# S6E1B3xG register map
Vendor: Cypress; File version: 2.1
CPU: CM0PLUS r0p1, little endian, no MPU, no FPU, 2 interrupt priority bits
Registers are 8-bit, read-write, reset 0x0 unless marked. A register's access mark holds for its fields unless they carry their own. Offsets are from the block's base; [hi:lo] are bit positions; {n}, {i} and the like mark numbered series.

## GPIO — I/O Port Registers
Base 0x40033000
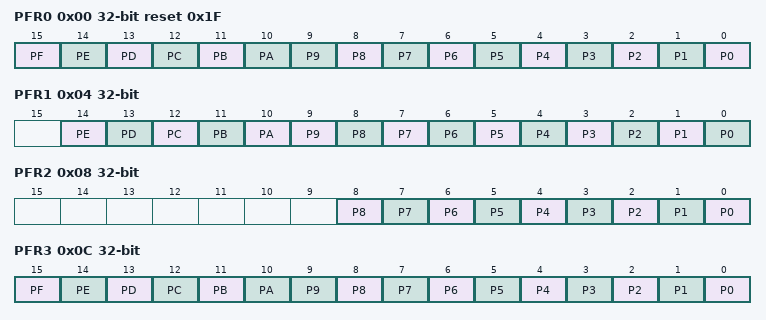
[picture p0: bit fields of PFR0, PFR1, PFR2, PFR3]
0x00 PFR0 32-bit reset 0x1F — Port Function Setting Register 0 [BHW]
  [15] PF — Bit15 of PFR0
  [14] PE — Bit14 of PFR0
  [13] PD — Bit13 of PFR0
  [12] PC — Bit12 of PFR0
  [11] PB — Bit11 of PFR0
  [10] PA — Bit10 of PFR0
  [n] P{n} (n=0..9) — Bit{n} of PFR0
0x04 PFR1 32-bit — Port Function Setting Register 1 [BHW]
  [14] PE — Bit14 of PFR1
  [13] PD — Bit13 of PFR1
  [12] PC — Bit12 of PFR1
  [11] PB — Bit11 of PFR1
  [10] PA — Bit10 of PFR1
  [n] P{n} (n=0..9) — Bit{n} of PFR1
0x08 PFR2 32-bit — Port Function Setting Register 2 [BHW]
  [n] P{n} (n=0..8) — Bit{n} of PFR2
0x0C PFR3 32-bit — Port Function Setting Register 3 [BHW]
  [15] PF — Bit15 of PFR3
  [14] PE — Bit14 of PFR3
  [13] PD — Bit13 of PFR3
  [12] PC — Bit12 of PFR3
  [11] PB — Bit11 of PFR3
  [10] PA — Bit10 of PFR3
  [n] P{n} (n=0..9) — Bit{n} of PFR3
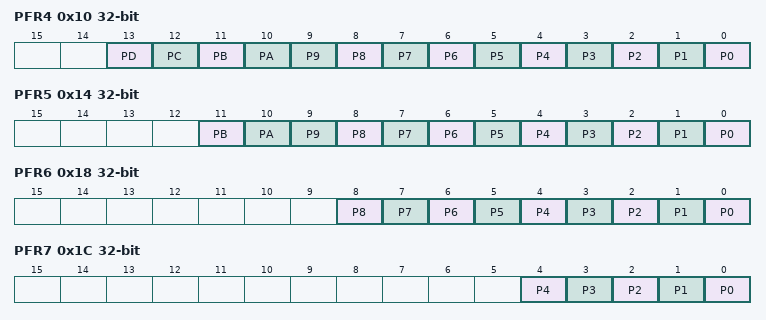
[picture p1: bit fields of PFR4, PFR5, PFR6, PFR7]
0x10 PFR4 32-bit — Port Function Setting Register 4 [HW]
  [13] PD — Bit13 of PFR4
  [12] PC — Bit12 of PFR4
  [11] PB — Bit11 of PFR4
  [10] PA — Bit10 of PFR4
  [n] P{n} (n=0..9) — Bit{n} of PFR4
0x14 PFR5 32-bit — Port Function Setting Register 5 [BHW]
  [11] PB — Bit11 of PFR5
  [10] PA — Bit10 of PFR5
  [n] P{n} (n=0..9) — Bit{n} of PFR5
0x18 PFR6 32-bit — Port Function Setting Register 6 [BHW]
  [n] P{n} (n=0..8) — Bit{n} of PFR6
0x1C PFR7 32-bit — Port Function Setting Register 7 [BHW]
  [n] P{n} (n=0..4) — Bit{n} of PFR7
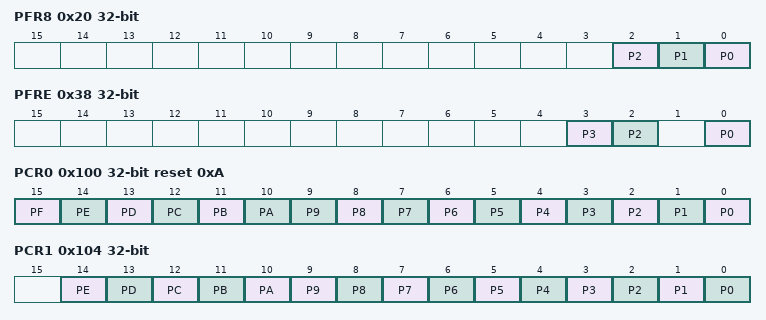
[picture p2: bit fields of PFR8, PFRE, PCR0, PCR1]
0x20 PFR8 32-bit — Port Function Setting Register 8 [BHW]
  [2] P2 — Bit2 of PFR8
  [1] P1 — Bit1 of PFR8
  [0] P0 — Bit0 of PFR8
0x24 PFR9 32-bit reset not defined — Port Function Setting Register 9 [BHW]
0x28 PFRA 32-bit reset not defined — Port Function Setting Register A [BHW]
0x2C PFRB 32-bit reset not defined — Port Function Setting Register B [BHW]
0x30 PFRC 32-bit reset not defined — Port Function Setting Register C [BHW]
0x34 PFRD 32-bit reset not defined — Port Function Setting Register D [BHW]
0x38 PFRE 32-bit — Port Function Setting Register E [BHW]
  [3] P3 — Bit3 of PFRE
  [2] P2 — Bit2 of PFRE
  [0] P0 — Bit0 of PFRE
0x3C PFRF 32-bit reset not defined — Port Function Setting Register F [BHW]
0x100 PCR0 32-bit reset 0xA — Pull-up Setting Register 0 [BHW]
  [15] PF — Bit15 of PCR0
  [14] PE — Bit14 of PCR0
  [13] PD — Bit13 of PCR0
  [12] PC — Bit12 of PCR0
  [11] PB — Bit11 of PCR0
  [10] PA — Bit10 of PCR0
  [n] P{n} (n=0..9) — Bit{n} of PCR0
0x104 PCR1 32-bit — Pull-up Setting Register 1 [BHW]
  [14] PE — Bit14 of PCR1
  [13] PD — Bit13 of PCR1
  [12] PC — Bit12 of PCR1
  [11] PB — Bit11 of PCR1
  [10] PA — Bit10 of PCR1
  [n] P{n} (n=0..9) — Bit{n} of PCR1
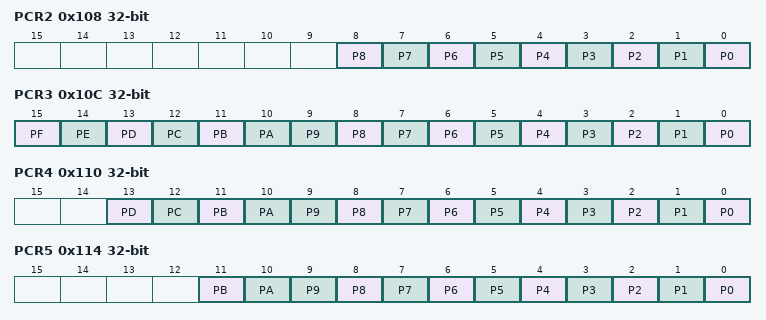
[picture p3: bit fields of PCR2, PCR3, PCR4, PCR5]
0x108 PCR2 32-bit — Pull-up Setting Register 2 [BHW]
  [n] P{n} (n=0..8) — Bit{n} of PCR2
0x10C PCR3 32-bit — Pull-up Setting Register 3 [BHW]
  [15] PF — Bit15 of PCR3
  [14] PE — Bit14 of PCR3
  [13] PD — Bit13 of PCR3
  [12] PC — Bit12 of PCR3
  [11] PB — Bit11 of PCR3
  [10] PA — Bit10 of PCR3
  [n] P{n} (n=0..9) — Bit{n} of PCR3
0x110 PCR4 32-bit — Pull-up Setting Register 4 [BHW]
  [13] PD — Bit13 of PCR4
  [12] PC — Bit12 of PCR4
  [11] PB — Bit11 of PCR4
  [10] PA — Bit10 of PCR4
  [n] P{n} (n=0..9) — Bit{n} of PCR4
0x114 PCR5 32-bit — Pull-up Setting Register 5 [BHW]
  [11] PB — Bit11 of PCR5
  [10] PA — Bit10 of PCR5
  [n] P{n} (n=0..9) — Bit{n} of PCR5
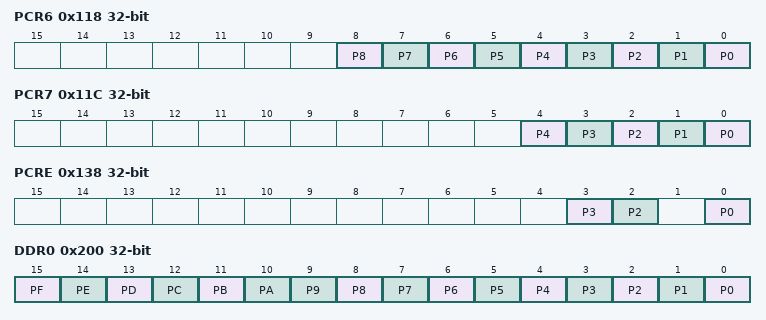
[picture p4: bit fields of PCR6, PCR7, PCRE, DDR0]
0x118 PCR6 32-bit — Pull-up Setting Register 6 [BHW]
  [n] P{n} (n=0..8) — Bit{n} of PCR6
0x11C PCR7 32-bit — Pull-up Setting Register 7 [BHW]
  [n] P{n} (n=0..4) — Bit{n} of PCR7
0x124 PCR9 32-bit reset not defined — Pull-up Setting Register 9 [BHW]
0x128 PCRA 32-bit reset not defined — Pull-up Setting Register A [BHW]
0x12C PCRB 32-bit reset not defined — Pull-up Setting Register B [BHW]
0x130 PCRC 32-bit reset not defined — Pull-up Setting Register C [BHW]
0x134 PCRD 32-bit reset not defined — Pull-up Setting Register D [BHW]
0x138 PCRE 32-bit — Pull-up Setting Register E [BHW]
  [3] P3 — Bit3 of PCRE
  [2] P2 — Bit2 of PCRE
  [0] P0 — Bit0 of PCRE
0x13C PCRF 32-bit reset not defined — Pull-up Setting Register F [BHW]
0x200 DDR0 32-bit — Port input/output Direction Setting Register 0 [BHW]
  [15] PF — Bit15 of DDR0
  [14] PE — Bit14 of DDR0
  [13] PD — Bit13 of DDR0
  [12] PC — Bit12 of DDR0
  [11] PB — Bit11 of DDR0
  [10] PA — Bit10 of DDR0
  [n] P{n} (n=0..9) — Bit{n} of DDR0
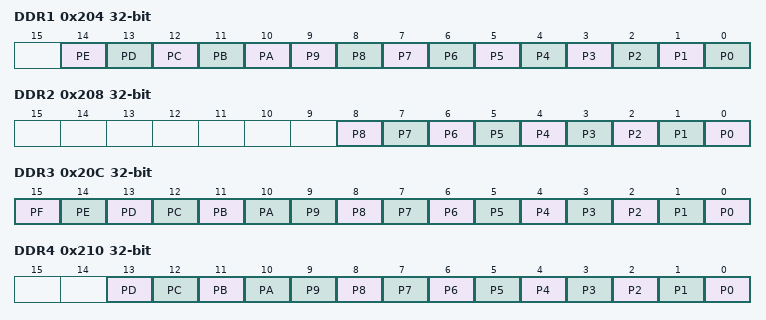
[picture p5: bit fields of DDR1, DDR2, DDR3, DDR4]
0x204 DDR1 32-bit — Port input/output Direction Setting Register 1 [BHW]
  [14] PE — Bit14 of DDR1
  [13] PD — Bit13 of DDR1
  [12] PC — Bit12 of DDR1
  [11] PB — Bit11 of DDR1
  [10] PA — Bit10 of DDR1
  [n] P{n} (n=0..9) — Bit{n} of DDR1
0x208 DDR2 32-bit — Port input/output Direction Setting Register 2 [BHW]
  [n] P{n} (n=0..8) — Bit{n} of DDR2
0x20C DDR3 32-bit — Port input/output Direction Setting Register 3 [BHW]
  [15] PF — Bit15 of DDR3
  [14] PE — Bit14 of DDR3
  [13] PD — Bit13 of DDR3
  [12] PC — Bit12 of DDR3
  [11] PB — Bit11 of DDR3
  [10] PA — Bit10 of DDR3
  [n] P{n} (n=0..9) — Bit{n} of DDR3
0x210 DDR4 32-bit — Port input/output Direction Setting Register 4 [BHW]
  [13] PD — Bit13 of DDR4
  [12] PC — Bit12 of DDR4
  [11] PB — Bit11 of DDR4
  [10] PA — Bit10 of DDR4
  [n] P{n} (n=0..9) — Bit{n} of DDR4
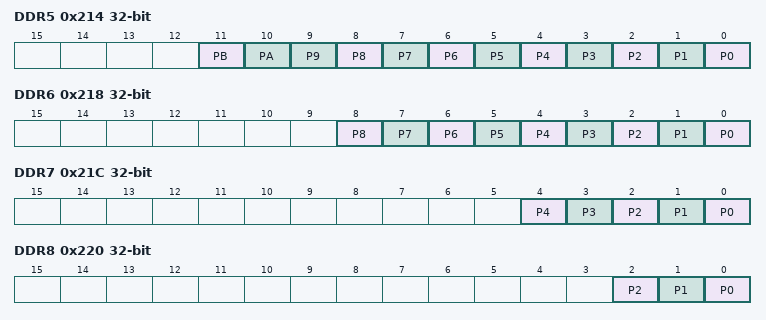
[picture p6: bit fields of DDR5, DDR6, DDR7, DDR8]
0x214 DDR5 32-bit — Port input/output Direction Setting Register 5 [BHW]
  [11] PB — Bit11 of DDR5
  [10] PA — Bit10 of DDR5
  [n] P{n} (n=0..9) — Bit{n} of DDR5
0x218 DDR6 32-bit — Port input/output Direction Setting Register 6 [BHW]
  [n] P{n} (n=0..8) — Bit{n} of DDR6
0x21C DDR7 32-bit — Port input/output Direction Setting Register 7 [BHW]
  [n] P{n} (n=0..4) — Bit{n} of DDR7
0x220 DDR8 32-bit — Port input/output Direction Setting Register 8 [BHW]
  [2] P2 — Bit2 of DDR8
  [1] P1 — Bit1 of DDR8
  [0] P0 — Bit0 of DDR8
0x224 DDR9 32-bit reset not defined — Port input/output Direction Setting Register 9 [BHW]
0x228 DDRA 32-bit reset not defined — Port input/output Direction Setting Register A [BHW]
0x22C DDRB 32-bit reset not defined — Port input/output Direction Setting Register B [BHW]
0x230 DDRC 32-bit reset not defined — Port input/output Direction Setting Register C [BHW]
0x234 DDRD 32-bit reset not defined — Port input/output Direction Setting Register D [BHW]
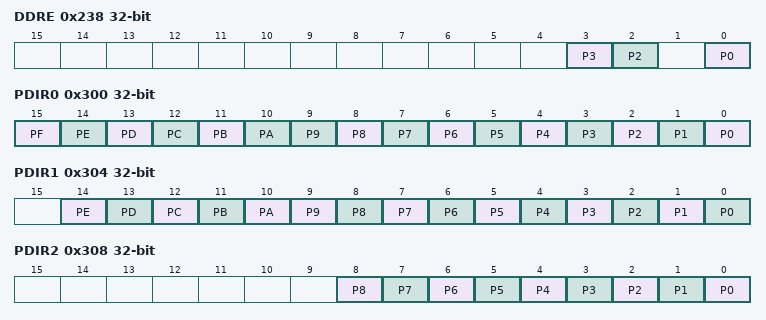
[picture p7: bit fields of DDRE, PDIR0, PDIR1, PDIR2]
0x238 DDRE 32-bit — Port input/output Direction Setting Register E [BHW]
  [3] P3 — Bit3 of DDRE
  [2] P2 — Bit2 of DDRE
  [0] P0 — Bit0 of DDRE
0x23C DDRF 32-bit reset not defined — Port input/output Direction Setting Register F [BHW]
0x300 PDIR0 32-bit ro — Port Input Data Register 0 [BHW]
  [15] PF rw — Bit15 of PDIR0
  [14] PE rw — Bit14 of PDIR0
  [13] PD rw — Bit13 of PDIR0
  [12] PC rw — Bit12 of PDIR0
  [11] PB rw — Bit11 of PDIR0
  [10] PA rw — Bit10 of PDIR0
  [n] P{n} rw (n=0..9) — Bit{n} of PDIR0
0x304 PDIR1 32-bit ro — Port Input Data Register 1 [BHW]
  [14] PE rw — Bit14 of PDIR1
  [13] PD rw — Bit13 of PDIR1
  [12] PC rw — Bit12 of PDIR1
  [11] PB rw — Bit11 of PDIR1
  [10] PA rw — Bit10 of PDIR1
  [n] P{n} rw (n=0..9) — Bit{n} of PDIR1
0x308 PDIR2 32-bit ro — Port Input Data Register 2 [BHW]
  [n] P{n} rw (n=0..8) — Bit{n} of PDIR2
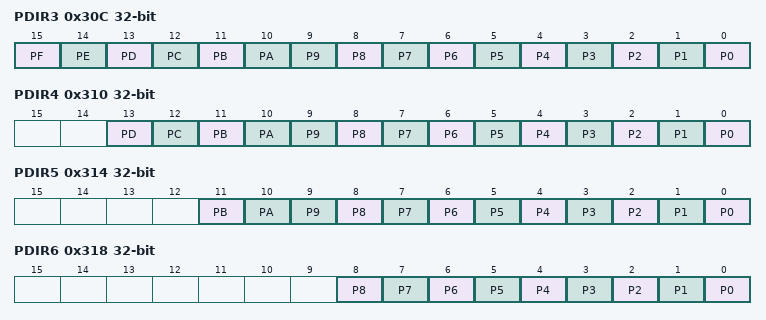
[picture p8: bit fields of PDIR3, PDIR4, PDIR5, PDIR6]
0x30C PDIR3 32-bit ro — Port Input Data Register 3 [BHW]
  [15] PF rw — Bit15 of PDIR3
  [14] PE rw — Bit14 of PDIR3
  [13] PD rw — Bit13 of PDIR3
  [12] PC rw — Bit12 of PDIR3
  [11] PB rw — Bit11 of PDIR3
  [10] PA rw — Bit10 of PDIR3
  [n] P{n} rw (n=0..9) — Bit{n} of PDIR3
0x310 PDIR4 32-bit ro — Port Input Data Register 4 [BHW]
  [13] PD rw — Bit13 of PDIR4
  [12] PC rw — Bit12 of PDIR4
  [11] PB rw — Bit11 of PDIR4
  [10] PA rw — Bit10 of PDIR4
  [n] P{n} rw (n=0..9) — Bit{n} of PDIR4
0x314 PDIR5 32-bit ro — Port Input Data Register 5 [BHW]
  [11] PB rw — Bit11 of PDIR5
  [10] PA rw — Bit10 of PDIR5
  [n] P{n} rw (n=0..9) — Bit{n} of PDIR5
0x318 PDIR6 32-bit ro — Port Input Data Register 6 [BHW]
  [n] P{n} rw (n=0..8) — Bit{n} of PDIR6
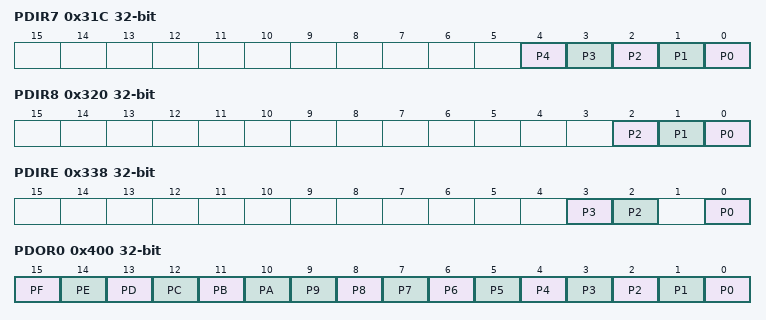
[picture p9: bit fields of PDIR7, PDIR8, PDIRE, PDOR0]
0x31C PDIR7 32-bit ro — Port Input Data Register 7 [BHW]
  [n] P{n} rw (n=0..4) — Bit{n} of PDIR7
0x320 PDIR8 32-bit ro — Port Input Data Register 8 [BHW]
  [2] P2 rw — Bit2 of PDIR8
  [1] P1 rw — Bit1 of PDIR8
  [0] P0 rw — Bit0 of PDIR8
0x324 PDIR9 32-bit ro reset not defined — Port Input Data Register 9 [BHW]
0x328 PDIRA 32-bit ro reset not defined — Port Input Data Register A [BHW]
0x32C PDIRB 32-bit ro reset not defined — Port Input Data Register B [BHW]
0x330 PDIRC 32-bit ro reset not defined — Port Input Data Register C [BHW]
0x334 PDIRD 32-bit ro reset not defined — Port Input Data Register D [BHW]
0x338 PDIRE 32-bit ro — Port Input Data Register E [BHW]
  [3] P3 rw — Bit3 of PDIRE
  [2] P2 rw — Bit2 of PDIRE
  [0] P0 rw — Bit0 of PDIRE
0x33C PDIRF 32-bit ro reset not defined — Port Input Data Register F [BHW]
0x400 PDOR0 32-bit — Port Output Data Register 0 [BHW]
  [15] PF — Bit15 of PDOR0
  [14] PE — Bit14 of PDOR0
  [13] PD — Bit13 of PDOR0
  [12] PC — Bit12 of PDOR0
  [11] PB — Bit11 of PDOR0
  [10] PA — Bit10 of PDOR0
  [n] P{n} (n=0..9) — Bit{n} of PDOR0
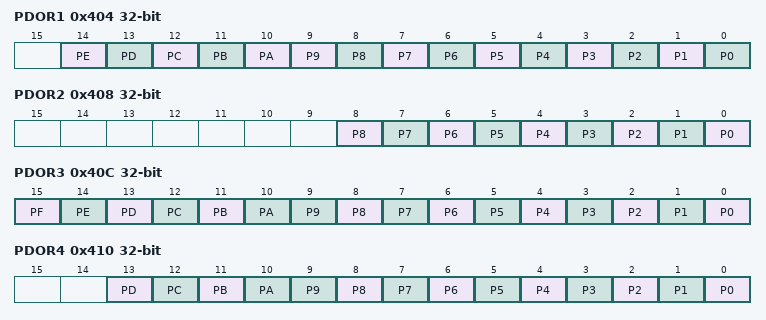
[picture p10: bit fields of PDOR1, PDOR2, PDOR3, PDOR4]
0x404 PDOR1 32-bit — Port Output Data Register 1 [BHW]
  [14] PE — Bit14 of PDOR1
  [13] PD — Bit13 of PDOR1
  [12] PC — Bit12 of PDOR1
  [11] PB — Bit11 of PDOR1
  [10] PA — Bit10 of PDOR1
  [n] P{n} (n=0..9) — Bit{n} of PDOR1
0x408 PDOR2 32-bit — Port Output Data Register 2 [BHW]
  [n] P{n} (n=0..8) — Bit{n} of PDOR2
0x40C PDOR3 32-bit — Port Output Data Register 3 [BHW]
  [15] PF — Bit15 of PDOR3
  [14] PE — Bit14 of PDOR3
  [13] PD — Bit13 of PDOR3
  [12] PC — Bit12 of PDOR3
  [11] PB — Bit11 of PDOR3
  [10] PA — Bit10 of PDOR3
  [n] P{n} (n=0..9) — Bit{n} of PDOR3
0x410 PDOR4 32-bit — Port Output Data Register 4 [BHW]
  [13] PD — Bit13 of PDOR4
  [12] PC — Bit12 of PDOR4
  [11] PB — Bit11 of PDOR4
  [10] PA — Bit10 of PDOR4
  [n] P{n} (n=0..9) — Bit{n} of PDOR4
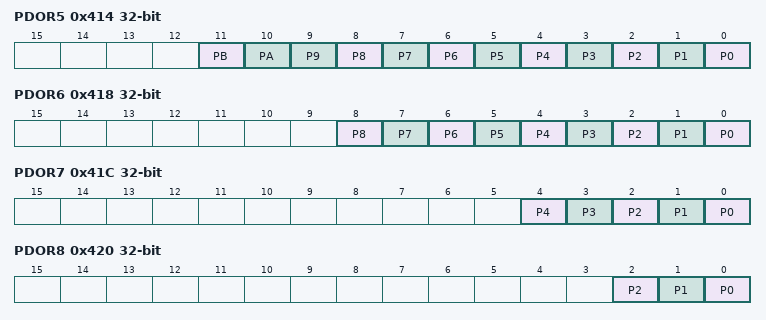
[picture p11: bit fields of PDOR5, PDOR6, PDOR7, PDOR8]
0x414 PDOR5 32-bit — Port Output Data Register 5 [BHW]
  [11] PB — Bit11 of PDOR5
  [10] PA — Bit10 of PDOR5
  [n] P{n} (n=0..9) — Bit{n} of PDOR5
0x418 PDOR6 32-bit — Port Output Data Register 6 [BHW]
  [n] P{n} (n=0..8) — Bit{n} of PDOR6
0x41C PDOR7 32-bit — Port Output Data Register 7 [BHW]
  [n] P{n} (n=0..4) — Bit{n} of PDOR7
0x420 PDOR8 32-bit — Port Output Data Register 8 [BHW]
  [2] P2 — Bit2 of PDOR8
  [1] P1 — Bit1 of PDOR8
  [0] P0 — Bit0 of PDOR8
0x424 PDOR9 32-bit reset not defined — Port Output Data Register 9 [BHW]
0x428 PDORA 32-bit reset not defined — Port Output Data Register A [BHW]
0x42C PDORB 32-bit reset not defined — Port Output Data Register B [BHW]
0x430 PDORC 32-bit reset not defined — Port Output Data Register C [BHW]
0x434 PDORD 32-bit reset not defined — Port Output Data Register D [BHW]
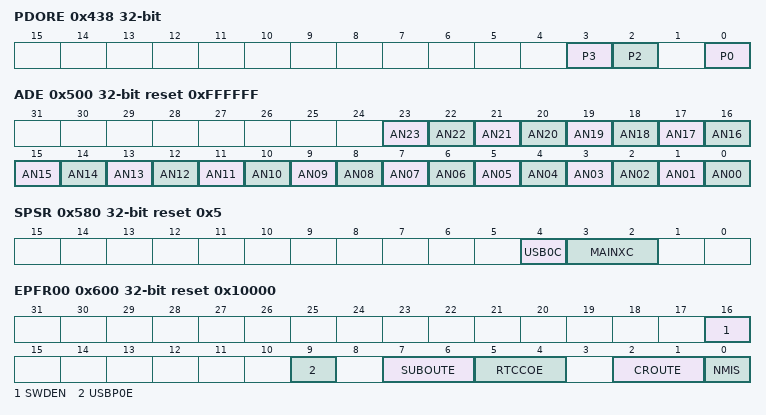
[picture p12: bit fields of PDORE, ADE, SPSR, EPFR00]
0x438 PDORE 32-bit — Port Output Data Register E [BHW]
  [3] P3 — Bit3 of PDORE
  [2] P2 — Bit2 of PDORE
  [0] P0 — Bit0 of PDORE
0x43C PDORF 32-bit reset not defined — Port Output Data Register F [BHW]
0x500 ADE 32-bit reset 0xFFFFFF — Analog Input Setting Register [BHW]
  [23] AN23 — Analog Input Ch.23 Setting Register
  [22] AN22 — Analog Input Ch.22 Setting Register
  [21] AN21 — Analog Input Ch.21 Setting Register
  [20] AN20 — Analog Input Ch.20 Setting Register
  [19] AN19 — Analog Input Ch.19 Setting Register
  [18] AN18 — Analog Input Ch.18 Setting Register
  [17] AN17 — Analog Input Ch.17 Setting Register
  [16] AN16 — Analog Input Ch.16 Setting Register
  [15] AN15 — Analog Input Ch.15 Setting Register
  [14] AN14 — Analog Input Ch.14 Setting Register
  [13] AN13 — Analog Input Ch.13 Setting Register
  [12] AN12 — Analog Input Ch.12 Setting Register
  [11] AN11 — Analog Input Ch.11 Setting Register
  [10] AN10 — Analog Input Ch.10 Setting Register
  [9] AN09 — Analog Input Ch.9 Setting Register
  [8] AN08 — Analog Input Ch.8 Setting Register
  [7] AN07 — Analog Input Ch.7 Setting Register
  [6] AN06 — Analog Input Ch.6 Setting Register
  [5] AN05 — Analog Input Ch.5 Setting Register
  [4] AN04 — Analog Input Ch.4 Setting Register
  [3] AN03 — Analog Input Ch.3 Setting Register
  [2] AN02 — Analog Input Ch.2 Setting Register
  [1] AN01 — Analog Input Ch.1 Setting Register
  [0] AN00 — Analog Input Ch.0 Setting Register
0x580 SPSR 32-bit reset 0x5 — Special Port Setting Register [BHW]
  [4] USB0C — USB (ch.0) Pin Setting Register
  [3:2] MAINXC — Main Clock (Oscillation) Pin Setting Register
0x600 EPFR00 32-bit reset 0x10000 — Extended Pin Function Setting Register 00 [BHW]
  [16] SWDEN — Serial Wire Debug Function Select bit
  [9] USBP0E — USB ch.0 Function Select bit 1
  [7:6] SUBOUTE — Sub clock divide output function select bit
  [5:4] RTCCOE — RTC clock output select bit
  [2:1] CROUTE — Internal high-speed CR Oscillation Output Function Select bit
  [0] NMIS — NMIX Function Select bit
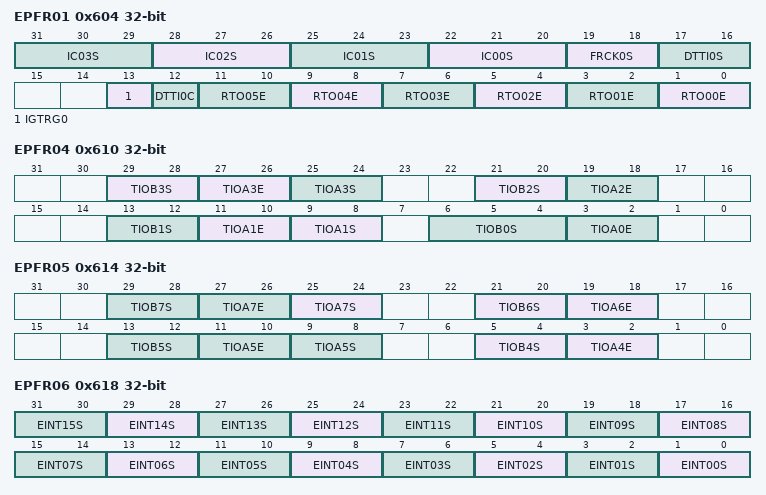
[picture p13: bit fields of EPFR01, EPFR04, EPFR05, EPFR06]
0x604 EPFR01 32-bit — Extended Pin Function Setting Register 01 [BHW]
  [3n+22:3n+20] IC{n:02}S (n=0..3) — IC{n:02} Input Select bits
  [19:18] FRCK0S — FRCK0 Input Select bits
  [17:16] DTTI0S — DTTIX0 Input Select bits
  [13] IGTRG0 — IGTRG0 Input Select bit
  [12] DTTI0C — DTTIX0 Function Select bit
  [2n+1:2n] RTO{n:02}E (n=0..5) — RTO{n:02} Output Select bits
0x610 EPFR04 32-bit — Extended Pin Function Setting Register 04 [BHW]
  [29:28] TIOB3S — TIOB3 Input Select bits
  [8n+3:8n+2] TIOA{n}E (n=0..3) — TIOA{n} Output Select bits
  [25:24] TIOA3S — TIOA3 Input Select bits
  [21:20] TIOB2S — TIOB2 Input Select bits
  [13:12] TIOB1S — TIOB1 Input Select bits
  [9:8] TIOA1S — TIOA1 Input Select bits
  [6:4] TIOB0S — TIOB0 Input Select bits
0x614 EPFR05 32-bit — Extended Pin Function Setting Register 05 [BHW]
  [8n-27:8n-28] TIOB{n}S (n=4..7) — TIOB{n} Input Select bits
  [8n-29:8n-30] TIOA{n}E (n=4..7) — TIOA{n} Output Select bits
  [25:24] TIOA7S — TIOA7 Input Select bits
  [9:8] TIOA5S — TIOA5 Input Select bits
0x618 EPFR06 32-bit — Extended Pin Function Setting Register 06 [BHW]
  [2n+1:2n] EINT{n:02}S (n=0..15) — External Interrupt {n:02} Input Select bits
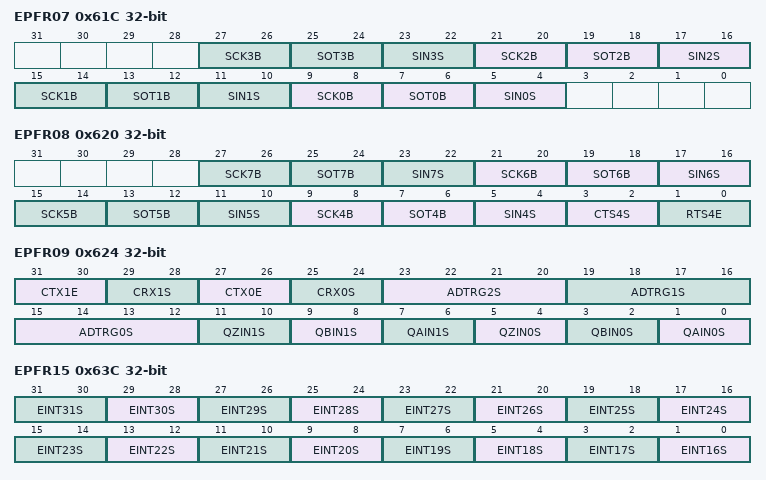
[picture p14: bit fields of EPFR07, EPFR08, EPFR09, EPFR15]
0x61C EPFR07 32-bit — Extended Pin Function Setting Register 07 [BHW]
  [6n+9:6n+8] SCK{n}B (n=0..3) — SCK{n} Input/Output Select bits
  [6n+7:6n+6] SOT{n}B (n=0..3) — SOT{n} Input/Output Select bits
  [6n+5:6n+4] SIN{n}S (n=0..3) — SIN{n} Input Select bits
0x620 EPFR08 32-bit — Extended Pin Function Setting Register 08 [BHW]
  [6n-15:6n-16] SCK{n}B (n=4..7) — SCK{n} Input/Output Select bits
  [6n-17:6n-18] SOT{n}B (n=4..7) — SOT{n} Input/Output Select bits
  [6n-19:6n-20] SIN{n}S (n=4..7) — SIN{n} Input Select bits
  [3:2] CTS4S — CTS4 Input Select bits
  [1:0] RTS4E — RTS4 Output Select bits
0x624 EPFR09 32-bit — Extended Pin Function Setting Register 09 [BHW]
  [31:30] CTX1E — CTX1E Output Select bits
  [29:28] CRX1S — CRX1S Input Select bits
  [27:26] CTX0E — CTX0E Output Select bits
  [25:24] CRX0S — CRX0S Input Select bits
  [23:20] ADTRG2S — ADTRG2 Input Select bits
  [19:16] ADTRG1S — ADTRG1 Input Select bits
  [15:12] ADTRG0S — ADTRG0 Input Select bits
  [11:10] QZIN1S — QZIN1S Input Select bits
  [9:8] QBIN1S — QBIN1S Input Select bits
  [7:6] QAIN1S — QAIN1S Input Select bits
  [5:4] QZIN0S — QZIN0S Input Select bits
  [3:2] QBIN0S — QBIN0S Input Select bits
  [1:0] QAIN0S — QAIN0S Input Select bits
0x63C EPFR15 32-bit — Extended Pin Function Setting Register 15 [BHW]
  [2n-31:2n-32] EINT{n}S (n=16..31) — External Interrupt {n} Input Select bits
0x640 EPFR16 32-bit — Extended Pin Function Setting Register 16 [BHW]
  [6n-39:6n-40] SCK{n}B (n=8..11) — SCK{n} Input/Output Select bits
  [6n-41:6n-42] SOT{n}B (n=8..11) — SOT{n} Input/Output Select bits
  [6n-43:6n-44] SIN{n}S (n=8..11) — SIN{n} Input Select bits
0x648 EPFR18 32-bit — Extended Pin Function Setting Register 18 [BHW]
  [3:2] CECR1B — CEC1 input/output selection bits
  [1:0] CECR0B — CEC0 input/output selection bits
0x65C EPFR23 32-bit — Extended Pin Function Setting Register 23 [BHW]
  [2n-131:2n-132] SCS{n}E (n=70..73) — SCS{n} Output Select bits
  [2n-119:2n-120] SCS{n}E (n=60..63) — SCS{n} Output Select bits
0x684 EPFR33 32-bit — Extended Pin Function Setting Register 33 [BHW]
  [27:26] CLK1E — CLK1 Output Select bits
  [25:24] VCC1E — VCC1 Output Select bits
  [23:22] VPEN1E — VPEN1 Output Select bits
  [21:20] RST1E — PST1 Output Select bits
  [19:18] DATA1B — DATA1 Bus Select bits
  [17:16] CIN1S — CIN1 Input Select bits
  [11:10] CLK0E — CLK0 Output Select bits
  [9:8] VCC0E — VCC0 Output Select bits
  [7:6] VPEN0E — VPEN0 Output Select bits
  [5:4] RST0E — RST0 Output Select bits
  [3:2] DATA0B — DATA0 Bus Select bits
  [1:0] CIN0S — CIN0 Input Select bits
0x688 EPFR34 32-bit — Extended Pin Function Setting Register 34 [BHW]
  [7:6] CTS1S — CTS1 Input Select bits
  [5:4] RTS1E — RTS1 Output Select bits
0x694 EPFR37 32-bit — Extended Pin Function Setting Register 37 [BHW]
  [27:26] SDO5E — MFSI2S I2SSDO5 Output Select bits
  [25:24] SDI5S — MFSI2S I2SDI5 Input Select bits
  [23:22] WS5B — I2SWS5 Input/Output Select bits
  [21:20] SCK5B — I2SCK5 Input/Output Select bits
  [19:18] MCK5E — I2SMCLK5 Output Select bits
  [17:16] MCK5S — I2SMCLK5 Input Select bits
0x698 EPFR38 32-bit — Extended Pin Function Setting Register 38 [BHW]
  [11:10] SDO6E — MFSI2S I2SDO6 Output Select bits
  [9:8] SDI6S — MFSI2S I2SDI6 Input Select bits
  [7:6] WS6B — I2SWS6 Input/Output Select bits
  [5:4] SCK6B — I2SCK6 Input/Output Select bits
  [3:2] MCK6E — I2SMCLK6 Output Select bits
  [1:0] MCK6S — I2SMCLK6 Input Select bits
0x700 PZR0 32-bit — Port Pseudo Open Drain Setting Register 0 [BHW]
  [15] PF — Bit15 of PZR0
  [14] PE — Bit14 of PZR0
  [13] PD — Bit13 of PZR0
  [12] PC — Bit12 of PZR0
  [11] PB — Bit11 of PZR0
  [10] PA — Bit10 of PZR0
  [n] P{n} (n=0..9) — Bit{n} of PZR0
0x704 PZR1 32-bit — Port Pseudo Open Drain Setting Register 1 [BHW]
  [14] PE — Bit14 of PZR1
  [13] PD — Bit13 of PZR1
  [12] PC — Bit12 of PZR1
  [11] PB — Bit11 of PZR1
  [10] PA — Bit10 of PZR1
  [n] P{n} (n=0..9) — Bit{n} of PZR1
0x708 PZR2 32-bit — Port Pseudo Open Drain Setting Register 2 [BHW]
  [n] P{n} (n=0..8) — Bit{n} of PZR2
0x70C PZR3 32-bit — Port Pseudo Open Drain Setting Register 3 [BHW]
  [15] PF — Bit15 of PZR3
  [14] PE — Bit14 of PZR3
  [13] PD — Bit13 of PZR3
  [12] PC — Bit12 of PZR3
  [11] PB — Bit11 of PZR3
  [10] PA — Bit10 of PZR3
  [n] P{n} (n=0..9) — Bit{n} of PZR3
0x710 PZR4 32-bit — Port Pseudo Open Drain Setting Register 4 [BHW]
  [13] PD — Bit13 of PZR4
  [12] PC — Bit12 of PZR4
  [11] PB — Bit11 of PZR4
  [10] PA — Bit10 of PZR4
  [n] P{n} (n=0..9) — Bit{n} of PZR4
0x714 PZR5 32-bit — Port Pseudo Open Drain Setting Register 5 [BHW]
  [11] PB — Bit11 of PZR5
  [10] PA — Bit10 of PZR5
  [n] P{n} (n=0..9) — Bit{n} of PZR5
0x718 PZR6 32-bit — Port Pseudo Open Drain Setting Register 6 [BHW]
  [n] P{n} (n=0..8) — Bit{n} of PZR6
0x71C PZR7 32-bit — Port Pseudo Open Drain Setting Register 7 [BHW]
  [n] P{n} (n=0..4) — Bit{n} of PZR7
0x720 PZR8 32-bit — Port Pseudo Open Drain Setting Register 8 [BHW]
  [2] P2 — Bit2 of PZR8
  [1] P1 — Bit1 of PZR8
  [0] P0 — Bit0 of PZR8
0x724 PZR9 32-bit reset not defined — Port Pseudo Open Drain Setting Register 9 [BHW]
0x728 PZRA 32-bit reset not defined — Port Pseudo Open Drain Setting Register A [BHW]
0x72C PZRB 32-bit reset not defined — Port Pseudo Open Drain Setting Register B [BHW]
0x730 PZRC 32-bit reset not defined — Port Pseudo Open Drain Setting Register C [BHW]
0x734 PZRD 32-bit reset not defined — Port Pseudo Open Drain Setting Register D [BHW]
0x738 PZRE 32-bit — Port Pseudo Open Drain Setting Register E [BHW]
  [3] P3 — Bit3 of PZRE
  [2] P2 — Bit2 of PZRE
  [0] P0 — Bit0 of PZRE
0x73C PZRF 32-bit reset not defined — Port Pseudo Open Drain Setting Register F [BHW]
0x740 LVDIE 32-bit — LVDI Input Setting Register [BHW]
  [0] LVDIE — LVDI Input select bit
0x900 FPOER0 32-bit wo — Fast GPIO Output Enable Register 0 [BHW]
  [15] PF rw — Bit15 of FPOER0
  [14] PE rw — Bit14 of FPOER0
  [13] PD rw — Bit13 of FPOER0
  [12] PC rw — Bit12 of FPOER0
  [11] PB rw — Bit11 of FPOER0
  [10] PA rw — Bit10 of FPOER0
  [n] P{n} rw (n=0..9) — Bit{n} of FPOER0
0x904 FPOER1 32-bit wo — Fast GPIO Output Enable Register 1 [BHW]
  [14] PE rw — Bit14 of FPOER1
  [13] PD rw — Bit13 of FPOER1
  [12] PC rw — Bit12 of FPOER1
  [11] PB rw — Bit11 of FPOER1
  [10] PA rw — Bit10 of FPOER1
  [n] P{n} rw (n=0..9) — Bit{n} of FPOER1
0x908 FPOER2 32-bit wo — Fast GPIO Output Enable Register 2 [BHW]
  [n] P{n} rw (n=0..8) — Bit{n} of FPOER2
0x90C FPOER3 32-bit wo — Fast GPIO Output Enable Register 3 [BHW]
  [15] PF rw — Bit15 of FPOER3
  [14] PE rw — Bit14 of FPOER3
  [13] PD rw — Bit13 of FPOER3
  [12] PC rw — Bit12 of FPOER3
  [11] PB rw — Bit11 of FPOER3
  [10] PA rw — Bit10 of FPOER3
  [n] P{n} rw (n=0..9) — Bit{n} of FPOER3
0x910 FPOER4 32-bit wo — Fast GPIO Output Enable Register 4 [BHW]
  [13] PD rw — Bit13 of FPOER4
  [12] PC rw — Bit12 of FPOER4
  [11] PB rw — Bit11 of FPOER4
  [10] PA rw — Bit10 of FPOER4
  [n] P{n} rw (n=0..9) — Bit{n} of FPOER4
0x914 FPOER5 32-bit wo — Fast GPIO Output Enable Register 5 [BHW]
  [11] PB rw — Bit11 of FPOER5
  [10] PA rw — Bit10 of FPOER5
  [n] P{n} rw (n=0..9) — Bit{n} of FPOER5
0x918 FPOER6 32-bit wo — Fast GPIO Output Enable Register 6 [BHW]
  [n] P{n} rw (n=0..8) — Bit{n} of FPOER6
0x91C FPOER7 32-bit wo — Fast GPIO Output Enable Register 7 [BHW]
  [n] P{n} rw (n=0..4) — Bit{n} of FPOER7
0x920 FPOER8 32-bit wo — Fast GPIO Output Enable Register 8 [BHW]
  [2] P2 rw — Bit2 of FPOER8
  [1] P1 rw — Bit1 of FPOER8
  [0] P0 rw — Bit0 of FPOER8
0x924 FPOER9 32-bit wo reset not defined — Fast GPIO Output Enable Register 9 [BHW]
0x928 FPOERA 32-bit wo reset not defined — Fast GPIO Output Enable Register A [BHW]
0x92C FPOERB 32-bit wo reset not defined — Fast GPIO Output Enable Register B [BHW]
0x930 FPOERC 32-bit wo reset not defined — Fast GPIO Output Enable Register C [BHW]
0x934 FPOERD 32-bit wo reset not defined — Fast GPIO Output Enable Register D [BHW]
0x938 FPOERE 32-bit wo — Fast GPIO Output Enable Register E [BHW]
  [3] P3 rw — Bit3 of FPOERE
  [2] P2 rw — Bit2 of FPOERE
  [0] P0 rw — Bit0 of FPOERE
0x93C FPOERF 32-bit wo reset not defined — Fast GPIO Output Enable Register F [BHW]

## Notices in the file
Copyright (C) 2013-2016, Cypress Semiconductor Corporation or a
subsidiary of Cypress Semiconductor Corporation.  All rights reserved.
This software, including source code, documentation and related
materials ("Software"), is owned by Cypress Semiconductor Corporation or
one of its subsidiaries ("Cypress") and is protected by and subject to
worldwide patent protection (United States and foreign), United States
copyright laws and international treaty provisions. Therefore, you may use
this Software only as provided in the license agreement accompanying the
software package from which you obtained this Software ("EULA").
If no EULA applies, Cypress hereby grants you a personal, non-exclusive,
non-transferable license to copy, modify, and compile the
Software source code solely for use in connection with Cypress's
integrated circuit products.  Any reproduction, modification, translation,
compilation, or representation of this Software except as specified
above is prohibited without the express written permission of Cypress.
Disclaimer: THIS SOFTWARE IS PROVIDED AS-IS, WITH NO
WARRANTY OF ANY KIND, EXPRESS OR IMPLIED, INCLUDING,
BUT NOT LIMITED TO, NONINFRINGEMENT, IMPLIED
WARRANTIES OF MERCHANTABILITY AND FITNESS FOR A
PARTICULAR PURPOSE. Cypress reserves the right to make
changes to the Software without notice. Cypress does not assume any
liability arising out of the application or use of the Software or any
product or circuit described in the Software. Cypress does not
authorize its products for use in any products where a malfunction or
failure of the Cypress product may reasonably be expected to result in
significant property damage, injury or death ("High Risk Product"). By
including Cypress's product in a High Risk Product, the manufacturer
of such system or application assumes all risk of such use and in doing
so agrees to indemnify Cypress against all liability.
